# STM32WBxxx_CM4 register map
File version: 1.5
CPU: CM4 r0p1, little endian, MPU, FPU, 4 interrupt priority bits
Registers are 32-bit, read-write, reset 0x0 unless marked. A register's access mark holds for its fields unless they carry their own. Offsets are from the block's base; [hi:lo] are bit positions; {n}, {i} and the like mark numbered series.

## PKA
Base 0x58002000
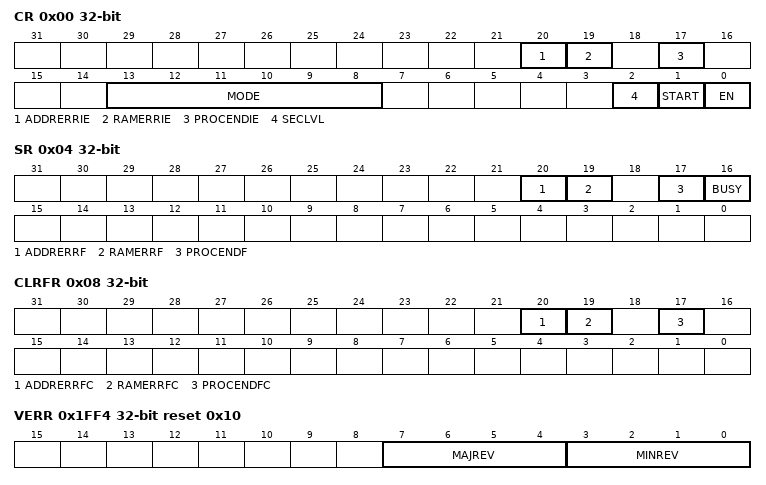
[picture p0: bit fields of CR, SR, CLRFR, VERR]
0x00 CR — Control register
  [20] ADDRERRIE — Address error interrupt enable
  [19] RAMERRIE — RAM error interrupt enable
  [17] PROCENDIE — End of operation interrupt enable
  [13:8] MODE — PKA Operation Mode
  [2] SECLVL — Security Enable
  [1] START — Start the operation
  [0] EN — Peripheral Enable
0x04 SR ro — PKA status register
  [20] ADDRERRF — Address error flag
  [19] RAMERRF — RAM error flag
  [17] PROCENDF — PKA End of Operation flag
  [16] BUSY — PKA Operation in progress
0x08 CLRFR — PKA clear flag register
  [20] ADDRERRFC — Clear Address error flag
  [19] RAMERRFC — Clear RAM error flag
  [17] PROCENDFC — Clear PKA End of Operation flag
0x1FF4 VERR ro reset 0x10 — PKA version register
  [7:4] MAJREV — Major revision
  [3:0] MINREV — Minor revision
0x1FF8 IPIDR ro reset 0x170061 — PKA identification register
  [31:0] ID — Identification Code
0x1FFC SIDR ro reset 0xA3C5DD08 — PKA size ID register
  [31:0] SID — Side Identification Code

## IPCC
Base 0x58000C00
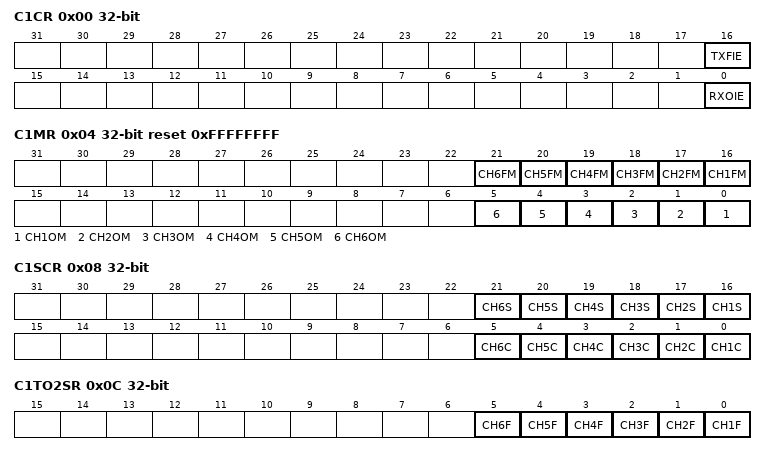
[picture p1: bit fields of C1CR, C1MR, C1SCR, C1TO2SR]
0x00 C1CR — Control register CPU1
  [16] TXFIE — processor 1 Transmit channel free interrupt enable
  [0] RXOIE — processor 1 Receive channel occupied interrupt enable
0x04 C1MR reset 0xFFFFFFFF — Mask register CPU1
  [n+15] CH{n}FM (n=1..6) — processor 1 Transmit channel {n} free interrupt mask
  [n-1] CH{n}OM (n=1..6) — processor 1 Receive channel {n} occupied interrupt enable
0x08 C1SCR wo — Status Set or Clear register CPU1
  [n+15] CH{n}S (n=1..6) — processor 1 Transmit channel {n} status set
  [n-1] CH{n}C (n=1..6) — processor 1 Receive channel {n} status clear
0x0C C1TO2SR ro — CPU1 to CPU2 status register
  [n-1] CH{n}F (n=1..6) — processor 1 transmit to process 2 Receive channel {n} status flag
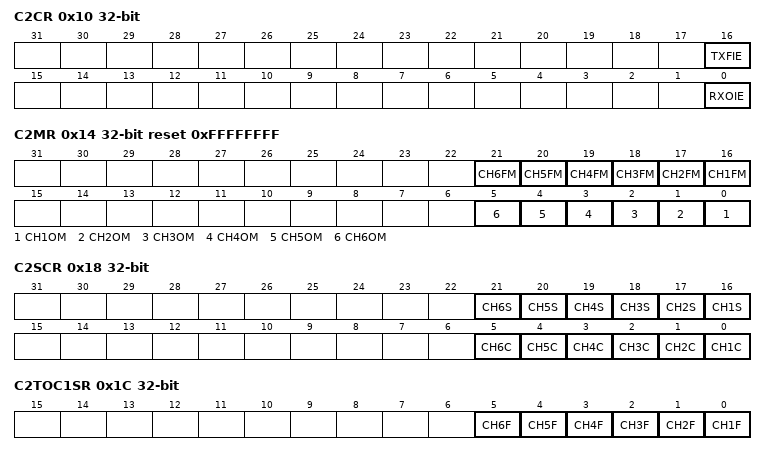
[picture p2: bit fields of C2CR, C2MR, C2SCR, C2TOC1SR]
0x10 C2CR — Control register CPU2
  [16] TXFIE — processor 2 Transmit channel free interrupt enable
  [0] RXOIE — processor 2 Receive channel occupied interrupt enable
0x14 C2MR reset 0xFFFFFFFF — Mask register CPU2
  [n+15] CH{n}FM (n=1..6) — processor 2 Transmit channel {n} free interrupt mask
  [n-1] CH{n}OM (n=1..6) — processor 2 Receive channel {n} occupied interrupt enable
0x18 C2SCR wo — Status Set or Clear register CPU2
  [n+15] CH{n}S (n=1..6) — processor 2 Transmit channel {n} status set
  [n-1] CH{n}C (n=1..6) — processor 2 Receive channel {n} status clear
0x1C C2TOC1SR ro — CPU2 to CPU1 status register
  [n-1] CH{n}F (n=1..6) — processor 2 transmit to process 1 Receive channel {n} status flag
0x3F0 HWCFGR ro reset 0x6 — IPCC Hardware configuration register
  [7:0] CHANNELS — Number of channels per CPU supported by the IP, range 1 to 16
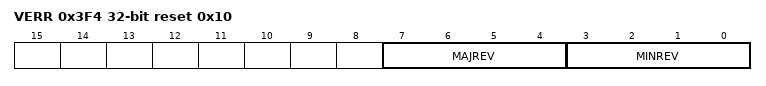
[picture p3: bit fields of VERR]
0x3F4 VERR ro reset 0x10 — IPCC version register
  [7:4] MAJREV — Major Revision
  [3:0] MINREV — Minor Revision
0x3F8 IPIDR ro reset 0x100071 — IPCC indentification register
  [31:0] IPID — Identification Code
0x3FC SIDR ro reset 0xA3C5DD01 — IPCC size indentification register
  [31:0] SID — Size Identification Code

## CRS — Clock recovery system
Base 0x40006000
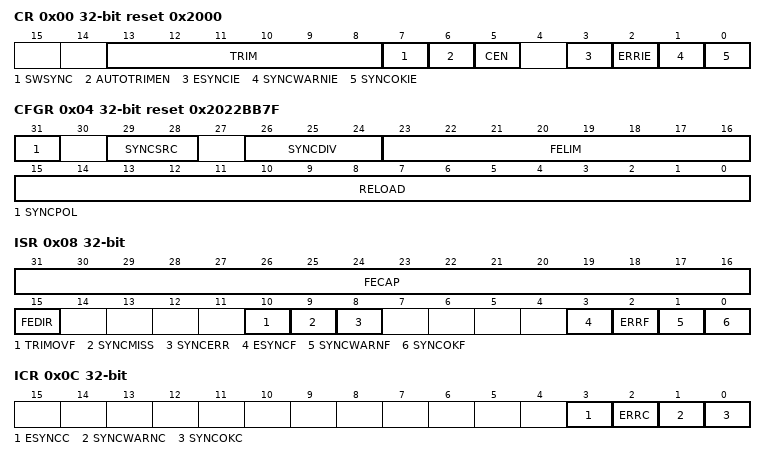
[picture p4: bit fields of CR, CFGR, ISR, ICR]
0x00 CR reset 0x2000 — CRS control register
  [13:8] TRIM — HSI48 oscillator smooth trimming
  [7] SWSYNC — Automatic trimming enable
  [6] AUTOTRIMEN — Automatic trimming enable
  [5] CEN — Frequency error counter enable
  [3] ESYNCIE — Expected SYNC interrupt enable
  [2] ERRIE — Synchronization or trimming error interrupt enable
  [1] SYNCWARNIE — SYNC warning interrupt enable
  [0] SYNCOKIE — SYNC event OK interrupt enable
0x04 CFGR reset 0x2022BB7F — CRS configuration register
  [31] SYNCPOL — SYNC polarity selection
  [29:28] SYNCSRC — SYNC signal source selection
  [26:24] SYNCDIV
  [23:16] FELIM — Frequency error limit
  [15:0] RELOAD — Counter reload value
0x08 ISR ro — CRS interrupt and status register
  [31:16] FECAP — Frequency error capture
  [15] FEDIR — Frequency error direction
  [10] TRIMOVF — Trimming overflow or underflow
  [9] SYNCMISS — SYNC missed
  [8] SYNCERR — SYNC error
  [3] ESYNCF — Expected SYNC flag
  [2] ERRF — Error flag
  [1] SYNCWARNF — SYNC warning flag
  [0] SYNCOKF — SYNC event OK flag
0x0C ICR — CRS interrupt flag clear register
  [3] ESYNCC — Expected SYNC clear flag
  [2] ERRC — Error clear flag
  [1] SYNCWARNC — warning clear flag
  [0] SYNCOKC — SYNC event OK clear flag
